VERSION ""

NS_ :

BS_:

BU_: CTRL DAQ SBFront1 SBFront2 SBRear1 SBRear2 SBCG

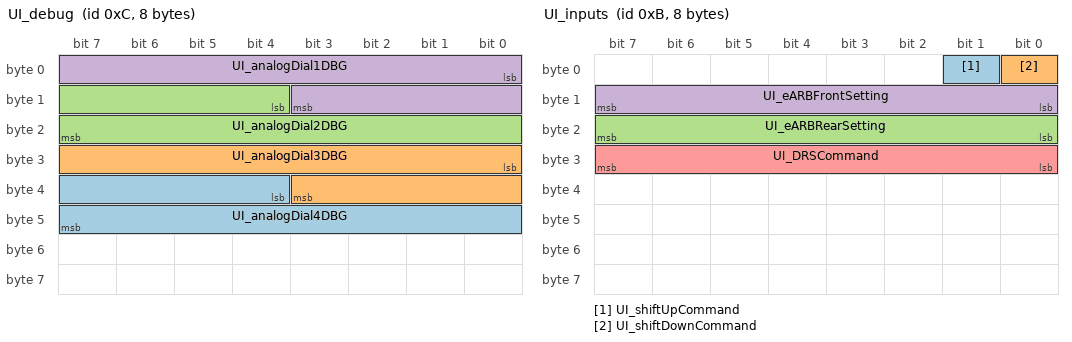
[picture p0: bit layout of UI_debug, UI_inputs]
BO_ 12 UI_debug: 8 Vector__XXX
 SG_ UI_analogDial4DBG : 36|12@1+ (1,0) [0|4095] "" Vector__XXX
 SG_ UI_analogDial3DBG : 24|12@1+ (1,0) [0|4095] "" Vector__XXX
 SG_ UI_analogDial2DBG : 12|12@1+ (1,0) [0|4095] "" Vector__XXX
 SG_ UI_analogDial1DBG : 0|12@1+ (1,0) [0|4095] "" Vector__XXX

BO_ 11 UI_inputs: 8 DAQ
 SG_ UI_shiftUpCommand : 1|1@1+ (1,0) [0|1] ""  CTRL
 SG_ UI_shiftDownCommand : 0|1@1+ (1,0) [0|1] ""  CTRL
 SG_ UI_eARBRearSetting : 16|8@1- (1,0) [-80|80] "deg"  CTRL
 SG_ UI_eARBFrontSetting : 8|8@1- (1,0) [-80|80] "deg"  CTRL
 SG_ UI_DRSCommand : 24|8@1- (1,0) [-80|80] "deg"  CTRL

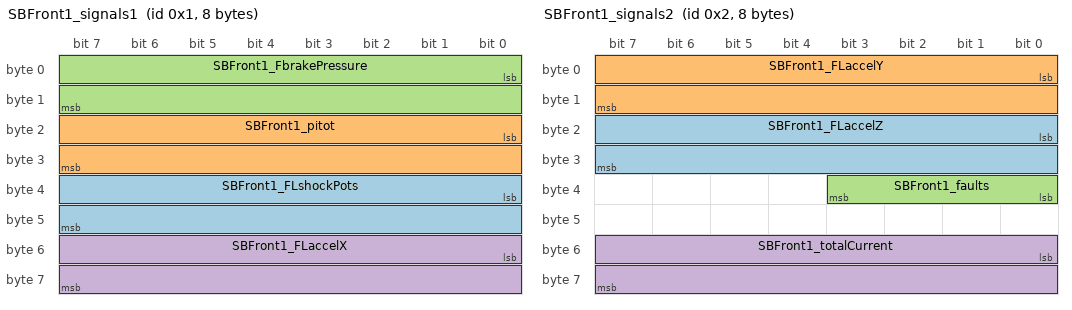
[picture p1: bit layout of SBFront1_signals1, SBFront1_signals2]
BO_ 1 SBFront1_signals1: 8 SBFront1
 SG_ SBFront1_FLshockPots : 32|16@1+ (1,0) [0|0] ""  DAQ
 SG_ SBFront1_pitot : 16|16@1+ (1,0) [0|0] ""  DAQ
 SG_ SBFront1_FbrakePressure : 0|16@1+ (1,0) [0|0] ""  DAQ
 SG_ SBFront1_FLaccelX : 48|16@1- (0.000190730497806599,-6.24966622162884) [-5|5] "g"  DAQ

BO_ 2 SBFront1_signals2: 8 SBFront1
 SG_ SBFront1_FLaccelZ : 16|16@1+ (1,0) [0|0] ""  DAQ
 SG_ SBFront1_FLaccelY : 0|16@1+ (1,0) [0|0] ""  DAQ
 SG_ SBFront1_faults : 32|4@1+ (1,0) [0|0] ""  DAQ
 SG_ SBFront1_totalCurrent : 48|16@1+ (6E-006,0) [0|0.39321] "A"  DAQ

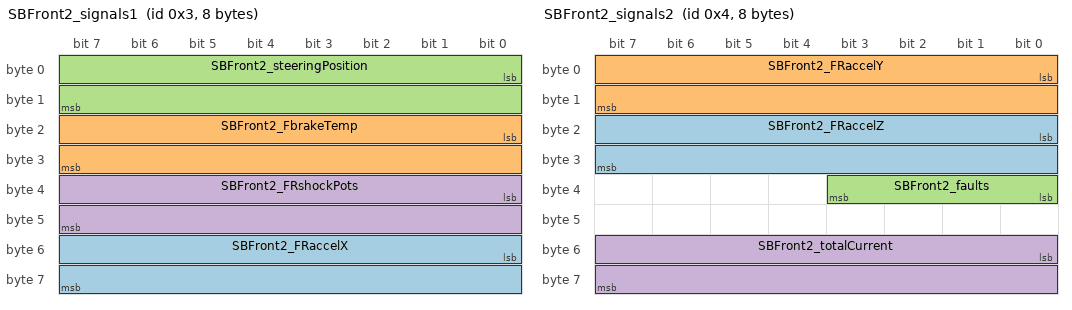
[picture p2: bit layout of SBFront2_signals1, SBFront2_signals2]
BO_ 3 SBFront2_signals1: 8 SBFront2
 SG_ SBFront2_FRaccelX : 48|16@1+ (1,0) [0|0] ""  DAQ
 SG_ SBFront2_FbrakeTemp : 16|16@1+ (1,0) [0|0] ""  DAQ
 SG_ SBFront2_steeringPosition : 0|16@1+ (1,0) [0|0] ""  DAQ
 SG_ SBFront2_FRshockPots : 32|16@1+ (1,0) [0|0] ""  DAQ

BO_ 4 SBFront2_signals2: 8 SBFront2
 SG_ SBFront2_FRaccelZ : 16|16@1+ (1,0) [0|0] ""  DAQ
 SG_ SBFront2_FRaccelY : 0|16@1+ (1,0) [0|0] ""  DAQ
 SG_ SBFront2_faults : 32|4@1+ (1,0) [0|0] ""  DAQ
 SG_ SBFront2_totalCurrent : 48|16@1+ (6E-006,0) [0|0.39321] "A"  DAQ

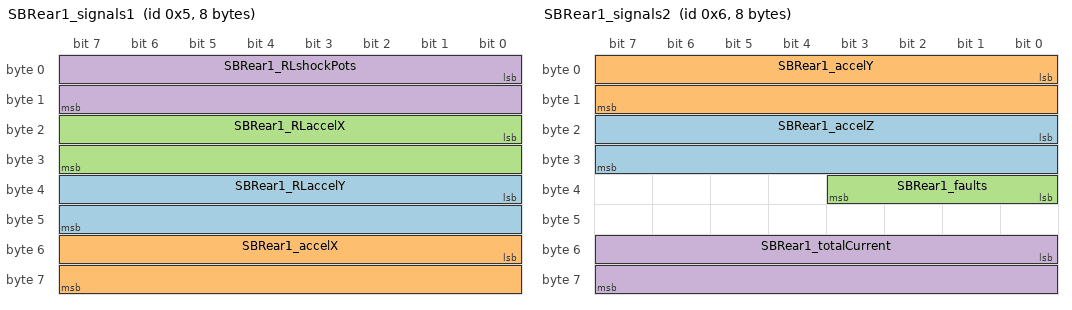
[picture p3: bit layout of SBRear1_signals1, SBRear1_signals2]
BO_ 5 SBRear1_signals1: 8 SBRear1
 SG_ SBRear1_RLaccelY : 32|16@1+ (1,0) [0|0] ""  DAQ
 SG_ SBRear1_accelX : 48|16@1+ (1,0) [0|0] ""  DAQ
 SG_ SBRear1_RLaccelX : 16|16@1+ (1,0) [0|0] ""  DAQ
 SG_ SBRear1_RLshockPots : 0|16@1+ (1,0) [0|0] ""  DAQ

BO_ 6 SBRear1_signals2: 8 SBRear1
 SG_ SBRear1_accelZ : 16|16@1+ (1,0) [0|0] ""  DAQ
 SG_ SBRear1_accelY : 0|16@1+ (1,0) [0|0] ""  DAQ
 SG_ SBRear1_faults : 32|4@1+ (1,0) [0|0] ""  DAQ
 SG_ SBRear1_totalCurrent : 48|16@1+ (6E-006,0) [0|0.39321] "A"  DAQ

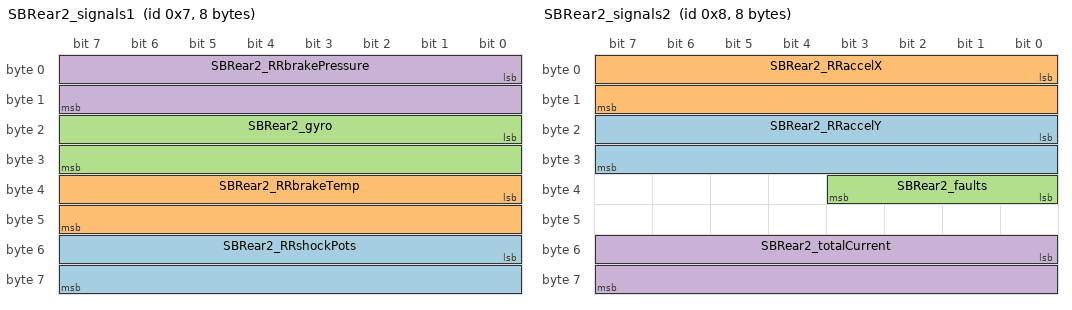
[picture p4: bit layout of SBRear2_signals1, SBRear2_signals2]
BO_ 7 SBRear2_signals1: 8 SBRear2
 SG_ SBRear2_RRshockPots : 48|16@1+ (1,0) [0|0] ""  DAQ
 SG_ SBRear2_RRbrakeTemp : 32|16@1+ (1,0) [0|0] ""  DAQ
 SG_ SBRear2_gyro : 16|16@1+ (1,0) [0|0] ""  DAQ
 SG_ SBRear2_RRbrakePressure : 0|16@1+ (1,0) [0|0] ""  DAQ

BO_ 8 SBRear2_signals2: 8 SBRear2
 SG_ SBRear2_RRaccelY : 16|16@1+ (1,0) [0|0] ""  DAQ
 SG_ SBRear2_RRaccelX : 0|16@1+ (1,0) [0|0] ""  DAQ
 SG_ SBRear2_faults : 32|4@1+ (1,0) [0|0] ""  DAQ
 SG_ SBRear2_totalCurrent : 48|16@1+ (6E-006,0) [0|0.39321] "A"  DAQ

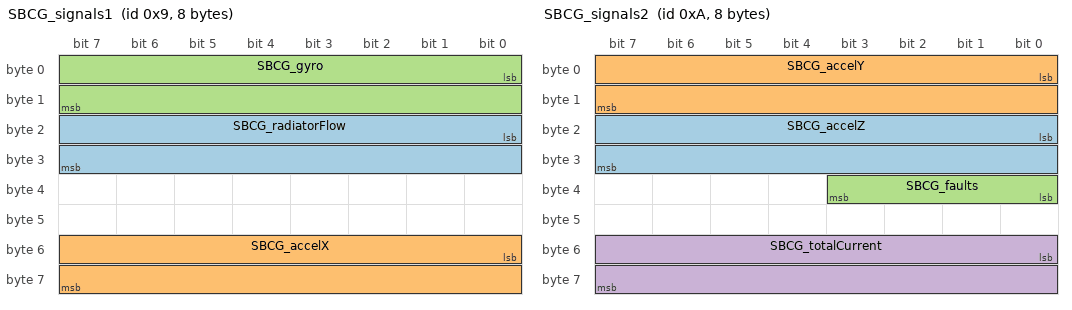
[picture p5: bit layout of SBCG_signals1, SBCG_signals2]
BO_ 9 SBCG_signals1: 8 SBCG
 SG_ SBCG_radiatorFlow : 16|16@1+ (1,0) [0|0] ""  DAQ
 SG_ SBCG_accelX : 48|16@1+ (1,0) [0|0] ""  DAQ
 SG_ SBCG_gyro : 0|16@1+ (1,0) [0|0] ""  DAQ

BO_ 10 SBCG_signals2: 8 SBCG
 SG_ SBCG_accelZ : 16|16@1+ (1,0) [0|0] ""  DAQ
 SG_ SBCG_accelY : 0|16@1+ (1,0) [0|0] ""  DAQ
 SG_ SBCG_faults : 32|4@1+ (1,0) [0|0] ""  DAQ
 SG_ SBCG_totalCurrent : 48|16@1+ (6E-006,0) [0|0.39321] "A"  DAQ

CM_ BU_ CTRL "Servo/shift control board";
CM_ BU_ DAQ "Dashboard Datalogger and Telemetry";
CM_ BU_ SBFront1 "Front sensor board 1";
CM_ BU_ SBFront2 "Front sensor board 2";
CM_ BU_ SBRear1 "Rear sensor board 1";
CM_ BU_ SBRear2 "Rear sensor board 2";
CM_ BU_ SBCG "Center of gravity sensor board";
BA_DEF_  "BusType" STRING ;
BA_DEF_ BO_  "GenMsgSendType" ENUM  "Cyclic";
BA_DEF_ BO_  "GenMsgCycleTime" INT 1 10000;
BA_DEF_DEF_  "BusType" "CAN";
BA_DEF_DEF_  "GenMsgSendType" "Cyclic";
BA_DEF_DEF_  "GenMsgCycleTime" 100;
BA_ "GenMsgCycleTime" BO_ 11 50;
BA_ "GenMsgCycleTime" BO_ 1 5;
BA_ "GenMsgCycleTime" BO_ 2 5;
BA_ "GenMsgCycleTime" BO_ 3 5;
BA_ "GenMsgCycleTime" BO_ 4 5;
BA_ "GenMsgCycleTime" BO_ 5 5;
BA_ "GenMsgCycleTime" BO_ 6 5;
BA_ "GenMsgCycleTime" BO_ 7 5;
BA_ "GenMsgCycleTime" BO_ 8 5;
BA_ "GenMsgCycleTime" BO_ 9 5;
BA_ "GenMsgCycleTime" BO_ 10 5;
